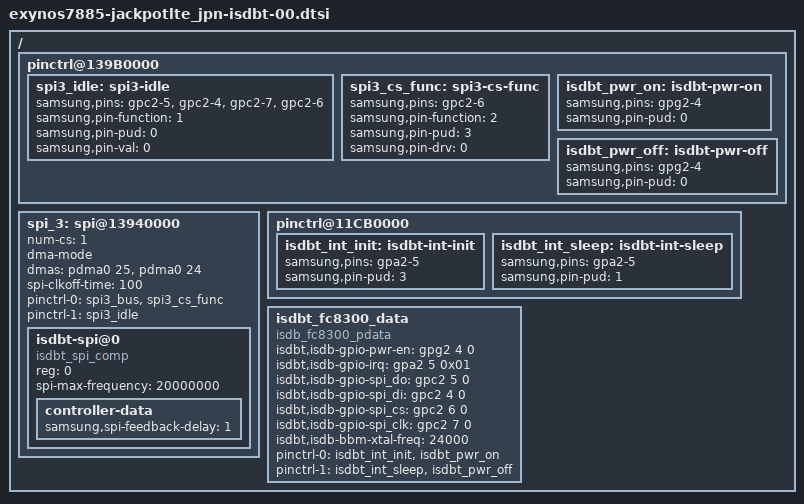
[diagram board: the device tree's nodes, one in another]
 /* Copyright (c) 2012-2014, The Linux Foundation. All rights reserved.
 *
 * This program is free software; you can redistribute it and/or modify
 * it under the terms of the GNU General Public License version 2 and
 * only version 2 as published by the Free Software Foundation.
 *
 * This program is distributed in the hope that it will be useful,
 * but WITHOUT ANY WARRANTY; without even the implied warranty of
 * MERCHANTABILITY or FITNESS FOR A PARTICULAR PURPOSE.  See the
 * GNU General Public License for more details.
 */

/{
	pinctrl@139B0000 {
		spi3_idle: spi3-idle {
			samsung,pins = "gpc2-5", "gpc2-4", "gpc2-7", "gpc2-6";
			samsung,pin-function = <1>;
			samsung,pin-pud = <0>;
			samsung,pin-val = <0>;
		};

		spi3_cs_func: spi3-cs-func {
			samsung,pins = "gpc2-6";
			samsung,pin-function = <2>;
			samsung,pin-pud = <3>;
			samsung,pin-drv = <0>;
		};
	};

	spi_3: spi@13940000 {
		#address-cells = <1>;
		#size-cells = <0>;
		num-cs = <1>;

		dma-mode;
		dmas = <&pdma0 25
			&pdma0 24>;

		status = "ok";
		spi-clkoff-time = <100>;

		pinctrl-names = "default", "idle";
		pinctrl-0 = <&spi3_bus &spi3_cs_func>;
		pinctrl-1 = <&spi3_idle>;

		isdbt-spi@0 {
			compatible = "isdbt_spi_comp";
			reg = <0>;
			spi-max-frequency = <20000000>;
			controller-data {
				samsung,spi-feedback-delay = <1>;
			};
		};
	};

	pinctrl@11CB0000 {
		isdbt_int_init: isdbt-int-init {
			samsung,pins = "gpa2-5";
			samsung,pin-pud = <3>;
		};
		isdbt_int_sleep: isdbt-int-sleep {
			samsung,pins = "gpa2-5";
			samsung,pin-pud = <1>;
		};
	};

	pinctrl@139B0000 {
		isdbt_pwr_on: isdbt-pwr-on {
			samsung,pins = "gpg2-4";
			samsung,pin-pud = <0>;
		};
		isdbt_pwr_off: isdbt-pwr-off {
			samsung,pins = "gpg2-4";
			samsung,pin-pud = <0>;
		};
	};

	isdbt_fc8300_data {
		compatible = "isdb_fc8300_pdata";
		isdbt,isdb-gpio-pwr-en = <&gpg2 4 0>;
		isdbt,isdb-gpio-irq = <&gpa2 5 0x01>;
		isdbt,isdb-gpio-spi_do = <&gpc2 5 0>;
		isdbt,isdb-gpio-spi_di = <&gpc2 4 0>;
		isdbt,isdb-gpio-spi_cs = <&gpc2 6 0>;
		isdbt,isdb-gpio-spi_clk = <&gpc2 7 0>;
		isdbt,isdb-bbm-xtal-freq = <24000>;

		pinctrl-names = "isdbt_on", "isdbt_off";
		pinctrl-0 = <&isdbt_int_init &isdbt_pwr_on>;
		pinctrl-1 = <&isdbt_int_sleep &isdbt_pwr_off>;
	};

};
